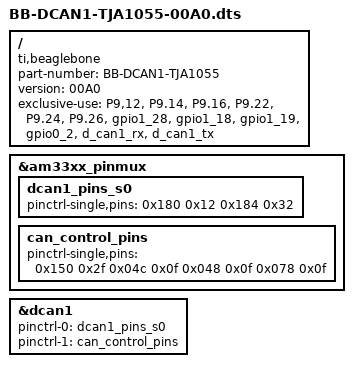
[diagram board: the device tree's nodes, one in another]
/dts-v1/;
/plugin/;
 
/ {
    compatible = "ti,beaglebone", "ti,beaglebone-black";
 
    /* identification */
    part-number = "BB-DCAN1-TJA1055";
    version = "00A0";

    exclusive-use=
        "P9,12",
        "P9.14",
        "P9.16",
        "P9.22",
        "P9.24",
        "P9.26",
        "gpio1_28",
        "gpio1_18",
        "gpio1_19",
        "gpio0_2",
        "d_can1_rx",
        "d_can1_tx";
 
    fragment@0 {
        target = <&am33xx_pinmux>;
        __overlay__ {
            dcan1_pins_s0: dcan1_pins_s0 {
                pinctrl-single,pins = <
                    0x180 0x12  /* d_can1_tx, SLEWCTRL_FAST | INPUT_PULLUP | MODE2 */
                    0x184 0x32  /* d_can1_rx, SLEWCTRL_FAST | RECV_ENABLE | INPUT_PULLUP | MODE2 */
                >;
            };
            can_control_pins: can_control_pins {
                pinctrl-single,pins = <
                    0x150 0x2f  /* ERR, Input, no pull   */
                    0x04c 0x0f  /* WAKE, OUTPUT, no pull */
                    0x048 0x0f  /* EN, OUTPUT, no pull   */
                    0x078 0x0f  /* STB, OUTPUT, no pull  */
                >;
            };
        };
    };
 
    fragment@1 {
        target = <&dcan1>;
        __overlay__ {
             #address-cells = <1>;
             #size-cells = <0>;
 
             status = "okay";
             pinctrl-names = "default";
             pinctrl-0 = <&dcan1_pins_s0>;
             pinctrl-1 = <&can_control_pins>;
        };
    };
};
